# ATA6614Q device description
Architecture: AVR8; Family: megaAVR
Registers are 8-bit, access not given, no defined reset value unless marked. A register's access mark holds for its fields unless they carry their own. Offsets are from the block's base; [hi:lo] are bit positions; 'fields as' and 'values as' point back to an identical list.

## EXTERNAL_INTERRUPT
Instances: EXTERNAL_INTERRUPT 0x00
0x3B PCIFR — Pin Change Interrupt Flag Register
  [2:0] PCIF — Pin Change Interrupt Flags
0x3C EIFR — External Interrupt Flag Register
  [1:0] INTF — External Interrupt Flags
0x3D EIMSK — External Interrupt Mask Register
  [1:0] INT — External Interrupt Request 1 Enable
0x68 PCICR — Pin Change Interrupt Control Register
  [2:0] PCIE — Pin Change Interrupt Enables
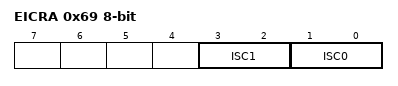
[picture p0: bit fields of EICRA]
0x69 EICRA — External Interrupt Control Register
  [3:2] ISC1 — External Interrupt Sense Control 1 Bits
    0=Low Level of INTX; 1=Any Logical Change of INTX; 2=Falling Edge of INTX; 3=Rising Edge of INTX
  [1:0] ISC0 — External Interrupt Sense Control 0 Bits
    values as ISC1
0x6B PCMSK0 — Pin Change Mask Register 0
  [7:0] PCINT — Pin Change Enable Masks
0x6C PCMSK1 — Pin Change Mask Register 1
  [6:0] PCINT (bit 8 of the value upward) — Pin Change Enable Masks
0x6D PCMSK2 — Pin Change Mask Register 2
  [7:0] PCINT (bit 16 of the value upward) — Pin Change Enable Masks

## SPI
Instances: SPI 0x00
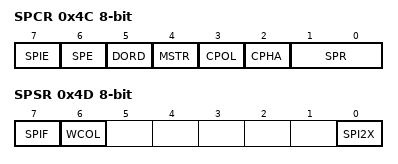
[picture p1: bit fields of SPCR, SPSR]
0x4C SPCR — SPI Control Register
  [7] SPIE — SPI Interrupt Enable
  [6] SPE — SPI Enable
  [5] DORD — Data Order
  [4] MSTR — Master/Slave Select
  [3] CPOL — Clock polarity
  [2] CPHA — Clock Phase
  [1:0] SPR — SPI Clock Rate Selects
    0=fosc/4; 1=fosc/16; 2=fosc/64; 3=fosc/128; 4=fosc/2; 5=fosc/8; 6=fosc/32; 7=fosc/64
0x4D SPSR — SPI Status Register
  [7] SPIF — SPI Interrupt Flag
  [6] WCOL — Write Collision Flag
  [0] SPI2X — Double SPI Speed Bit
0x4E SPDR — SPI Data Register

## WDT — Watchdog Timer
Instances: WDT 0x00
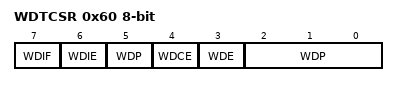
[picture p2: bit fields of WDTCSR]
0x60 WDTCSR — Watchdog Timer Control Register
  [7] WDIF — Watchdog Timeout Interrupt Flag
  [6] WDIE — Watchdog Timeout Interrupt Enable
  [4] WDCE — Watchdog Change Enable
  [3] WDE — Watch Dog Enable
  [5,2:0] WDP — Watchdog Timer Prescaler Bits
    0=Oscillator Cycles 2K; 1=Oscillator Cycles 4K; 2=Oscillator Cycles 8K; 3=Oscillator Cycles 16K; 4=Oscillator Cycles 32K; 5=Oscillator Cycles 64K; 6=Oscillator Cycles 128K; 7=Oscillator Cycles 256K; 8=Oscillator Cycles 512K; 9=Oscillator Cycles 1024K

## CPU
Instances: CPU 0x00
Parameters: CORE_VERSION=V2E
0x3E GPIOR0 — General Purpose I/O Register 0
0x4A GPIOR1 — General Purpose I/O Register 1
0x4B GPIOR2 — General Purpose I/O Register 2
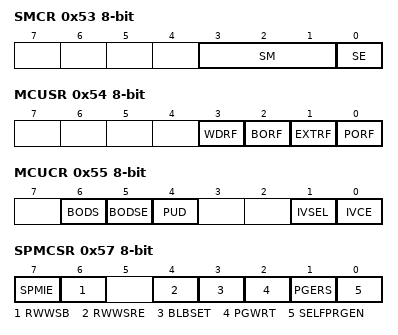
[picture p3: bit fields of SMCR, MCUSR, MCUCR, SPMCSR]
0x53 SMCR — Sleep Mode Control Register
  [3:1] SM — Sleep Mode Select Bits
    0=IDLE; 1=ADC (ADC Noise Reduction (If Available)); 2=PDOWN (Power Down); 3=PSAVE (Power Save); 6=STDBY (Standby); 7=ESTDBY (Extended Standby)
  [0] SE — Sleep Enable
0x54 MCUSR — MCU Status Register
  [3] WDRF — Watchdog Reset Flag
  [2] BORF — Brown-out Reset Flag
  [1] EXTRF — External Reset Flag
  [0] PORF — Power-on reset flag
0x55 MCUCR — MCU Control Register
  [6] BODS — BOD Sleep
  [5] BODSE — BOD Sleep Enable
  [4] PUD
  [1] IVSEL
  [0] IVCE
0x57 SPMCSR — Store Program Memory Control and Status Register
  [7] SPMIE — SPM Interrupt Enable
  [6] RWWSB — Read-While-Write Section Busy
  [4] RWWSRE — Read-While-Write section read enable
  [3] BLBSET — Boot Lock Bit Set
  [2] PGWRT — Page Write
  [1] PGERS — Page Erase
  [0] SELFPRGEN — Self Programming Enable
0x5D SP 16-bit bits used 11:0 — Stack Pointer
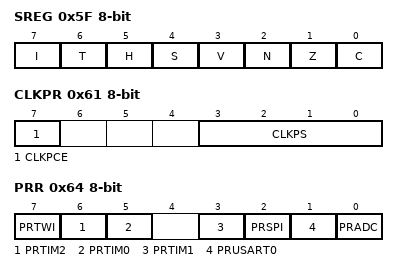
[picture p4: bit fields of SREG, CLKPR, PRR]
0x5F SREG — Status Register
  [7] I — Global Interrupt Enable
  [6] T — Bit Copy Storage
  [5] H — Half Carry Flag
  [4] S — Sign Bit
  [3] V — Two's Complement Overflow Flag
  [2] N — Negative Flag
  [1] Z — Zero Flag
  [0] C — Carry Flag
0x61 CLKPR — Clock Prescale Register
  [7] CLKPCE — Clock Prescaler Change Enable
  [3:0] CLKPS — Clock Prescaler Select Bits
    0=1; 1=2; 2=4; 3=8; 4=16; 5=32; 6=64; 7=128; 8=256
0x64 PRR — Power Reduction Register
  [7] PRTWI — Power Reduction TWI
  [6] PRTIM2 — Power Reduction Timer/Counter2
  [5] PRTIM0 — Power Reduction Timer/Counter0
  [3] PRTIM1 — Power Reduction Timer/Counter1
  [2] PRSPI — Power Reduction Serial Peripheral Interface
  [1] PRUSART0 — Power Reduction USART
  [0] PRADC — Power Reduction ADC
0x66 OSCCAL — Oscillator Calibration Value
  [7:0] OSCCAL — Oscillator Calibration
Value list OSCCAL_VALUE_ADDRESSES: 0=8_0_MHz

## EEPROM
Instances: EEPROM 0x00
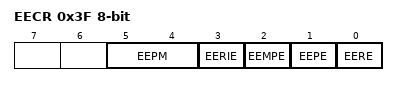
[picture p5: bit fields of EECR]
0x3F EECR — EEPROM Control Register
  [5:4] EEPM — EEPROM Programming Mode Bits
    0=Erase and Write in one operation; 1=Erase Only; 2=Write Only
  [3] EERIE — EEPROM Ready Interrupt Enable
  [2] EEMPE — EEPROM Master Write Enable
  [1] EEPE — EEPROM Write Enable
  [0] EERE — EEPROM Read Enable
0x40 EEDR — EEPROM Data Register
0x41 EEAR 16-bit bits used 9:0 — EEPROM Address Register Bytes
